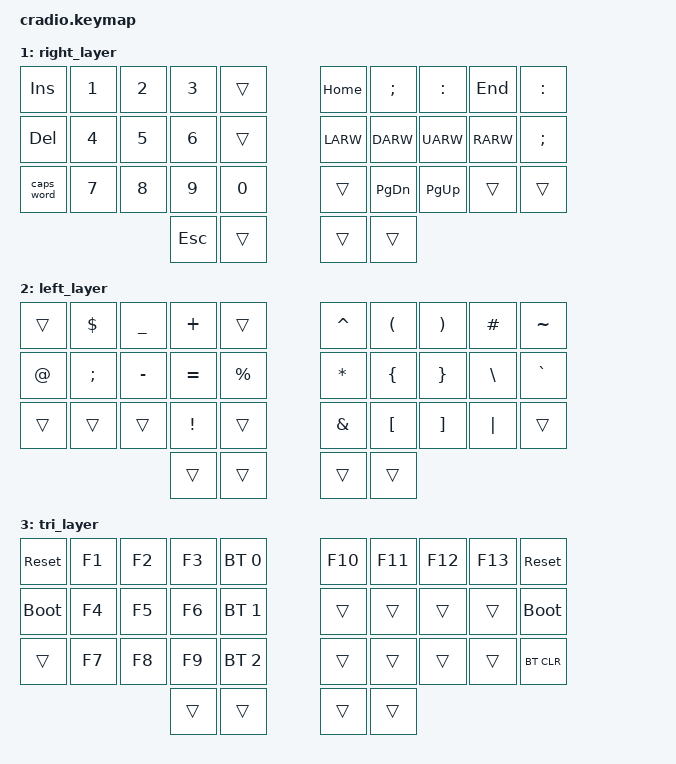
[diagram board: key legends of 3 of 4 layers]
// Copyright (c) 2022 The ZMK Contributors
// SPDX-License-Identifier: MIT

#include <behaviors.dtsi>
#include <dt-bindings/zmk/keys.h>
#include <dt-bindings/zmk/bt.h>

// Home row mods macro
#define HRML(k1,k2,k3,k4) &ht LSHFT k1  &ht LALT k2  &ht LCTRL k3  &ht LGUI k4
#define HRMR(k1,k2,k3,k4) &ht RGUI k1  &ht RCTRL k2  &ht RALT k3  &ht RSHFT k4

/ {
    behaviors {
        ht: hold_tap {
            compatible = "zmk,behavior-hold-tap";
            #binding-cells = <2>;
            flavor = "tap-preferred";
            tapping-term-ms = <220>;
            quick-tap-ms = <150>;
            require-prior-idle-ms = <100>;
            bindings = <&kp>, <&kp>;
        };
    };

    conditional_layers {
        compatible = "zmk,conditional-layers";
        tri_layer {
            if-layers = <1 2>;
            then-layer = <3>;
        };
    };

    keymap {
        compatible = "zmk,keymap";
        default_layer {
            bindings = <
        //╭──────────┬──────────┬──────────┬──────────┬──────────╮   ╭──────────┬──────────┬──────────┬──────────┬──────────╮
        //│  Q       │  W       │  E       │  R       │  T       │   │  Y       │  U       │  I       │  O       │  P       │
            &kp Q      &kp W      &kp E      &kp R      &kp T          &kp Y      &kp U      &kp I      &kp O      &kp P
        //├──────────┼──────────┼──────────┼──────────┼──────────┤   ├──────────┼──────────┼──────────┼──────────┼──────────┤
        //│  A       │  S       │  D       │  F       │  G       │   │  H       │  J       │  K       │  L       │ ' "      │
            HRML(A,        S,         D,         F)     &kp G          &kp H      HRMR(J,        K,         L,        SQT)
        //├──────────┼──────────┼──────────┼──────────┼──────────┤   ├──────────┼──────────┼──────────┼──────────┼──────────┤
        //│  Z       │  X       │  C       │  V       │  B       │   │  N       │  M       │ , <      │ . >      │ / ?      │
            &kp Z      &kp X      &kp C      &kp V      &kp B          &kp N      &kp M      &kp COMMA  &kp DOT    &kp FSLH
        //╰──────────┴──────────┴──────────┼──────────┼──────────┤   ├──────────┼──────────┼──────────┴──────────┴──────────╯
                                            &kp ENTER   &lt 2 TAB     &lt 1 SPACE &kp BSPC
        //                                 ╰──────────┴──────────╯   ╰──────────┴──────────╯
            >;
        };

        right_layer {
            bindings = <
        //╭──────────┬──────────┬──────────┬──────────┬──────────╮   ╭──────────┬──────────┬──────────┬──────────┬──────────╮        
        //│ INSERT   │  1       │  2       │  3       │          │   │ HOME     │ PAGE DN  │ PAGE UP  │ END      │  :       │
            &kp INS    &kp N1     &kp N2     &kp N3     &trans         &kp HOME   &kp SEMI  &kp COLON  &kp END    &kp COLON
        //├──────────┼──────────┼──────────┼──────────┼──────────┤   ├──────────┼──────────┼──────────┼──────────┼──────────┤
        //│ DELETE   │  4       │  5       │  6       │          │   │ LEFT     │ DOWN     │ UP       │ RIGHT    │  ;       │
            &kp DEL    &kp N4     &kp N5     &kp N6     &trans         &kp LARW   &kp DARW   &kp UARW   &kp RARW   &kp SEMI
        //├──────────┼──────────┼──────────┼──────────┼──────────┤   ├──────────┼──────────┼──────────┼──────────┼──────────┤
        //│ CAPS     │  7       │  8       │  9       │  0       │   │          │          │          │          │          │
           &caps_word  &kp N7     &kp N8     &kp N9     &kp N0         &trans     &kp PG_DN  &kp PG_UP     &trans     &trans
        //╰──────────┴──────────┴──────────┼──────────┼──────────┤   ├──────────┼──────────┼──────────┴──────────┴──────────╯
                                             &kp ESC    &trans         &trans     &trans
        //                                 ╰──────────┴──────────╯   ╰──────────┴──────────╯
            >;
        };

        left_layer {
            bindings = <
        //╭──────────┬──────────┬──────────┬──────────┬──────────╮   ╭──────────┬──────────┬──────────┬──────────┬──────────╮
        //│          │  [       │  {       │  }       │          │   │  ^       │  (       │  )       │  ]       │  ~       │
            &trans     &kp DLLR   &kp UNDER  &kp PLUS   &trans         &kp CARET  &kp LPAR   &kp RPAR   &kp HASH   &kp TILDE
        //├──────────┼──────────┼──────────┼──────────┼──────────┤   ├──────────┼──────────┼──────────┼──────────┼──────────┤
        //│  !       │  @       │  #       │  $       │  %       │   │  *       │  -       │  =       │  \       │  `       │
            &kp AT    &kp SEMI   &kp MINUS   &kp EQUAL   &kp PRCNT      &kp ASTRK  &kp LBRC   &kp RBRC  &kp BSLH   &kp GRAVE
        //├──────────┼──────────┼──────────┼──────────┼──────────┤   ├──────────┼──────────┼──────────┼──────────┼──────────┤
        //│          │          │          │          │          │   │  &       │  _       │  +       │  │       │          │
            &trans     &trans     &trans     &kp EXCL    &trans         &kp AMPS   &kp LBKT   &kp RBKT   &kp PIPE   &trans
        //╰──────────┴──────────┴──────────┼──────────┼──────────┤   ├──────────┼──────────┼──────────┴──────────┴──────────╯
                                             &trans     &trans         &trans     &trans
        //                                 ╰──────────┴──────────╯   ╰──────────┴──────────╯
            >;
        };

        tri_layer {
            bindings = <
        //╭──────────┬──────────┬──────────┬──────────┬──────────╮   ╭──────────┬──────────┬──────────┬──────────┬──────────╮
        //│ RESET    │          │          │          │PROFILE 0 │   │          │          │          │          │  RESET   │
           &sys_reset  &kp F1     &kp F2     &kp F3    &bt BT_SEL 0    &kp F10     &kp F11     &kp F12   &kp F13    &sys_reset
        //├──────────┼──────────┼──────────┼──────────┼──────────┤   ├──────────┼──────────┼──────────┼──────────┼──────────┤
        //│BOOTLOADER│          │          │          │PROFILE 1 │   │          │          │          │          │BOOTLOADER│
          &bootloader  &kp F4     &kp F5     &kp F6     &bt BT_SEL 1    &trans     &trans     &trans     &trans    &bootloader
        //├──────────┼──────────┼──────────┼──────────┼──────────┤   ├──────────┼──────────┼──────────┼──────────┼──────────┤
        //│          │          │          │ CLEAR BT │PROFILE 2 │   │          │          │          │          │          │
            &trans     &kp F7     &kp F8    &kp F9    &bt BT_SEL 2    &trans     &trans     &trans     &trans     &bt BT_CLR
        //╰──────────┴──────────┴──────────┼──────────┼──────────┤   ├──────────┼──────────┼──────────┴──────────┴──────────╯
                                             &trans     &trans         &trans     &trans
        //                                 ╰──────────┴──────────╯   ╰──────────┴──────────╯
            >;
        };
    };
};
